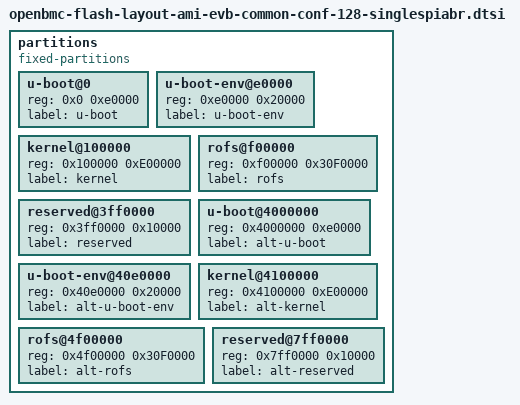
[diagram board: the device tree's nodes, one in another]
// SPDX-License-Identifier: GPL-2.0+
//
// 128MB flash layout: non-redundant image with common RW partition
//

partitions {
       compatible = "fixed-partitions";
       #address-cells = <1>;
       #size-cells = <1>;

       u-boot@0 {
               reg = <0x0 0xe0000>; // 896KB
               label = "u-boot";
       };

       u-boot-env@e0000 {
               reg = <0xe0000 0x20000>; // 128KB
               label = "u-boot-env";
       };

       kernel@100000 {
               reg = <0x100000 0xE00000>; // 14MB
               label = "kernel";
       };

       rofs@f00000 {
               reg = <0xf00000 0x30F0000>; // 49MB
               label = "rofs";
       };

    reserved@3ff0000 {
        reg = <0x3ff0000 0x10000>; // 64kb
        label = "reserved";
    };

    u-boot@4000000 {
            reg = <0x4000000 0xe0000>; // 896KB
            label = "alt-u-boot";
    };

    u-boot-env@40e0000 {
            reg = <0x40e0000 0x20000>; // 128KB
            label = "alt-u-boot-env";
    };

    kernel@4100000 {
            reg = <0x4100000 0xE00000>; // 14MB
            label = "alt-kernel";
    };

    rofs@4f00000 {
            reg = <0x4f00000 0x30F0000>; // 49MB
            label = "alt-rofs";
    };

    reserved@7ff0000 {
        reg = <0x7ff0000 0x10000>; // 64kb
        label = "alt-reserved";
    };
};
